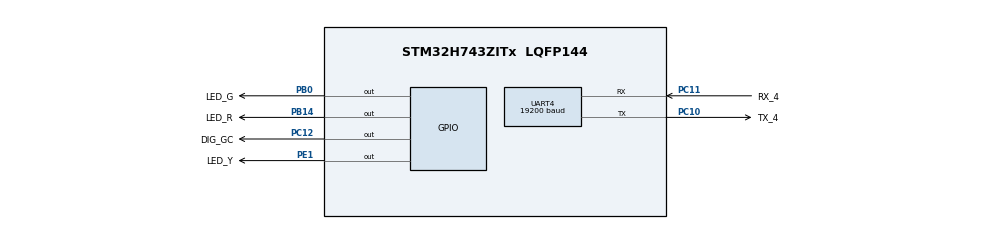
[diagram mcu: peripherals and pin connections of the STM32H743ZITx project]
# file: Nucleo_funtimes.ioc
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Mcu.Family=STM32H7
Mcu.Name=STM32H743ZITx
Mcu.Package=LQFP144
NVIC.PriorityGroup=NVIC_PRIORITYGROUP_4
PB0.GPIO_Label=LED_G
PB0.Signal=GPIO_Output
PB14.GPIO_Label=LED_R
PB14.Signal=GPIO_Output
PC10.GPIO_Label=TX_4
PC10.GPIO_PuPd=GPIO_PULLUP
PC10.Mode=Asynchronous
PC10.Signal=UART4_TX
PC11.GPIO_Label=RX_4
PC11.GPIO_PuPd=GPIO_PULLUP
PC11.Mode=Asynchronous
PC11.Signal=UART4_RX
PC12.GPIO_Label=DIG_GC
PC12.Signal=GPIO_Output
PE1.GPIO_Label=LED_Y
PE1.Signal=GPIO_Output
ProjectManager.HeapSize=0x200
ProjectManager.StackSize=0x400
ProjectManager.TargetToolchain=STM32CubeIDE
RCC.ADCFreq_Value=129000000
RCC.APB1Freq_Value=64000000
RCC.APB2Freq_Value=64000000
RCC.APB3Freq_Value=64000000
RCC.APB4Freq_Value=64000000
RCC.CortexFreq_Value=64000000
RCC.HCLKFreq_Value=64000000
RCC.SYSCLKFreq_VALUE=64000000
RCC.USBFreq_Value=129000000
UART4.BaudRate=19200
board=custom

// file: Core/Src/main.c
/* USER CODE BEGIN Header */
/**
  ******************************************************************************
  * @file           : main.c
  * @brief          : Main program body
  ******************************************************************************
  * @attention
  *
  * <h2><center>&copy; Copyright (c) 2019 STMicroelectronics.
  * All rights reserved.</center></h2>
  *
  * This software component is licensed by ST under BSD 3-Clause license,
  * the "License"; You may not use this file except in compliance with the
  * License. You may obtain a copy of the License at:
  *                        opensource.org/licenses/BSD-3-Clause
  *
  ******************************************************************************
  */
/* USER CODE END Header */

#include "main.h"

/* USER CODE BEGIN Includes */
#include "string.h"
#include "app.h"
// #include "mbed.h"
/* USER CODE END Includes */

UART_HandleTypeDef huart4;

void SystemClock_Config(void);
static void MX_GPIO_Init(void);
static void MX_UART4_Init(void);
/* USER CODE BEGIN PFP */
// void TX4_print(const char* msg);
/* USER CODE END PFP */

int main(void)
{

  /* MCU Configuration--------------------------------------------------------*/

  /* Reset of all peripherals, Initializes the Flash interface and the Systick. */
  HAL_Init();

  /* Configure the system clock */
  SystemClock_Config();

  /* Initialize all configured peripherals */
  MX_GPIO_Init();
  MX_UART4_Init();

  /* Infinite loop */
  /* USER CODE BEGIN WHILE */

  main_fn();

    /* USER CODE END WHILE */

}

void SystemClock_Config(void)
{
  RCC_OscInitTypeDef RCC_OscInitStruct = {0};
  RCC_ClkInitTypeDef RCC_ClkInitStruct = {0};
  RCC_PeriphCLKInitTypeDef PeriphClkInitStruct = {0};

  /** Supply configuration update enable
  */
  HAL_PWREx_ConfigSupply(PWR_LDO_SUPPLY);
  /** Configure the main internal regulator output voltage
  */
  __HAL_PWR_VOLTAGESCALING_CONFIG(PWR_REGULATOR_VOLTAGE_SCALE3);

  while(!__HAL_PWR_GET_FLAG(PWR_FLAG_VOSRDY)) {}
  /** Initializes the CPU, AHB and APB busses clocks
  */
  RCC_OscInitStruct.OscillatorType = RCC_OSCILLATORTYPE_HSI;
  RCC_OscInitStruct.HSIState = RCC_HSI_DIV1;
  RCC_OscInitStruct.HSICalibrationValue = RCC_HSICALIBRATION_DEFAULT;
  RCC_OscInitStruct.PLL.PLLState = RCC_PLL_NONE;
  if (HAL_RCC_OscConfig(&RCC_OscInitStruct) != HAL_OK)
  {
    Error_Handler();
  }
  /** Initializes the CPU, AHB and APB busses clocks
  */
  RCC_ClkInitStruct.ClockType = RCC_CLOCKTYPE_HCLK|RCC_CLOCKTYPE_SYSCLK
                              |RCC_CLOCKTYPE_PCLK1|RCC_CLOCKTYPE_PCLK2
                              |RCC_CLOCKTYPE_D3PCLK1|RCC_CLOCKTYPE_D1PCLK1;
  RCC_ClkInitStruct.SYSCLKSource = RCC_SYSCLKSOURCE_HSI;
  RCC_ClkInitStruct.SYSCLKDivider = RCC_SYSCLK_DIV1;
  RCC_ClkInitStruct.AHBCLKDivider = RCC_HCLK_DIV1;
  RCC_ClkInitStruct.APB3CLKDivider = RCC_APB3_DIV1;
  RCC_ClkInitStruct.APB1CLKDivider = RCC_APB1_DIV1;
  RCC_ClkInitStruct.APB2CLKDivider = RCC_APB2_DIV1;
  RCC_ClkInitStruct.APB4CLKDivider = RCC_APB4_DIV1;

  if (HAL_RCC_ClockConfig(&RCC_ClkInitStruct, FLASH_LATENCY_0) != HAL_OK)
  {
    Error_Handler();
  }
  PeriphClkInitStruct.PeriphClockSelection = RCC_PERIPHCLK_UART4;
  PeriphClkInitStruct.Usart234578ClockSelection = RCC_USART234578CLKSOURCE_D2PCLK1;
  if (HAL_RCCEx_PeriphCLKConfig(&PeriphClkInitStruct) != HAL_OK)
  {
    Error_Handler();
  }
}

static void MX_UART4_Init(void)
{

  huart4.Instance = UART4;
  huart4.Init.BaudRate = 115200;
  huart4.Init.WordLength = UART_WORDLENGTH_8B;
  huart4.Init.StopBits = UART_STOPBITS_1;
  huart4.Init.Parity = UART_PARITY_NONE;
  huart4.Init.Mode = UART_MODE_TX_RX;
  huart4.Init.HwFlowCtl = UART_HWCONTROL_NONE;
  huart4.Init.OverSampling = UART_OVERSAMPLING_16;
  huart4.Init.OneBitSampling = UART_ONE_BIT_SAMPLE_DISABLE;
  huart4.Init.ClockPrescaler = UART_PRESCALER_DIV1;
  huart4.AdvancedInit.AdvFeatureInit = UART_ADVFEATURE_NO_INIT;
  if (HAL_UART_Init(&huart4) != HAL_OK)
  {
    Error_Handler();
  }
  if (HAL_UARTEx_SetTxFifoThreshold(&huart4, UART_TXFIFO_THRESHOLD_1_8) != HAL_OK)
  {
    Error_Handler();
  }
  if (HAL_UARTEx_SetRxFifoThreshold(&huart4, UART_RXFIFO_THRESHOLD_1_8) != HAL_OK)
  {
    Error_Handler();
  }
  if (HAL_UARTEx_DisableFifoMode(&huart4) != HAL_OK)
  {
    Error_Handler();
  }

}

static void MX_GPIO_Init(void)
{
  GPIO_InitTypeDef GPIO_InitStruct = {0};

  /* GPIO Ports Clock Enable */
  __HAL_RCC_GPIOB_CLK_ENABLE();
  __HAL_RCC_GPIOC_CLK_ENABLE();
  __HAL_RCC_GPIOE_CLK_ENABLE();

  /*Configure GPIO pin Output Level */
  HAL_GPIO_WritePin(GPIOB, LED_G_Pin|LED_R_Pin, GPIO_PIN_RESET);

  /*Configure GPIO pin Output Level */
  HAL_GPIO_WritePin(DIG_GC_GPIO_Port, DIG_GC_Pin, GPIO_PIN_RESET);

  /*Configure GPIO pin Output Level */
  HAL_GPIO_WritePin(LED_Y_GPIO_Port, LED_Y_Pin, GPIO_PIN_RESET);

  /*Configure GPIO pins : LED_G_Pin LED_R_Pin */
  GPIO_InitStruct.Pin = LED_G_Pin|LED_R_Pin;
  GPIO_InitStruct.Mode = GPIO_MODE_OUTPUT_PP;
  GPIO_InitStruct.Pull = GPIO_NOPULL;
  GPIO_InitStruct.Speed = GPIO_SPEED_FREQ_LOW;
  HAL_GPIO_Init(GPIOB, &GPIO_InitStruct);

  /*Configure GPIO pin : DIG_GC_Pin */
  GPIO_InitStruct.Pin = DIG_GC_Pin;
  GPIO_InitStruct.Mode = GPIO_MODE_OUTPUT_PP;
  GPIO_InitStruct.Pull = GPIO_NOPULL;
  GPIO_InitStruct.Speed = GPIO_SPEED_FREQ_LOW;
  HAL_GPIO_Init(DIG_GC_GPIO_Port, &GPIO_InitStruct);

  /*Configure GPIO pin : LED_Y_Pin */
  GPIO_InitStruct.Pin = LED_Y_Pin;
  GPIO_InitStruct.Mode = GPIO_MODE_OUTPUT_PP;
  GPIO_InitStruct.Pull = GPIO_NOPULL;
  GPIO_InitStruct.Speed = GPIO_SPEED_FREQ_LOW;
  HAL_GPIO_Init(LED_Y_GPIO_Port, &GPIO_InitStruct);

}

/* USER CODE BEGIN 4 */
void TX4_print(char* msg){
	HAL_UART_Transmit(&huart4, (uint8_t*)msg, strlen(msg), 0xFFFF);
	HAL_UART_Transmit(&huart4, (uint8_t*)"\r\n", strlen("\r\n"), 0xFFFF);
}

/* USER CODE END 4 */

void Error_Handler(void)
{
}

/************************ (C) COPYRIGHT STMicroelectronics *****END OF FILE****/
